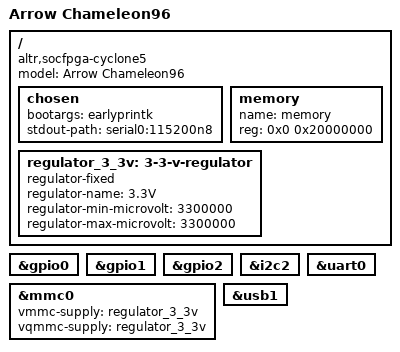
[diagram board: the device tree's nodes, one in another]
/*
 *  Copyright (C) 2017 Arrow Electronics, Inc.
 *
 * This program is free software; you can redistribute it and/or modify
 * it under the terms of the GNU General Public License as published by
 * the Free Software Foundation; either version 2 of the License, or
 * (at your option) any later version.
 *
 * This program is distributed in the hope that it will be useful,
 * but WITHOUT ANY WARRANTY; without even the implied warranty of
 * MERCHANTABILITY or FITNESS FOR A PARTICULAR PURPOSE.  See the
 * GNU General Public License for more details.
 *
 * You should have received a copy of the GNU General Public License
 * along with this program.  If not, see <http://www.gnu.org/licenses/>.
 */

#include "socfpga_cyclone5.dtsi"

/ {
	model = "Arrow Chameleon96";
	compatible = "altr,socfpga-cyclone5", "altr,socfpga";

	chosen {
		bootargs = "earlyprintk";
		stdout-path = "serial0:115200n8";
	};

	memory {
		name = "memory";
		device_type = "memory";
		reg = <0x0 0x20000000>; /* 512MB */
	};

	regulator_3_3v: 3-3-v-regulator {
		compatible = "regulator-fixed";
		regulator-name = "3.3V";
		regulator-min-microvolt = <3300000>;
		regulator-max-microvolt = <3300000>;
	};
};

&gpio0 {
	status = "okay";
};

&gpio1 {
	status = "okay";
};

&gpio2 {
	status = "okay";
};

&i2c2 {
	status = "okay";
};

&mmc0 {
	vmmc-supply = <&regulator_3_3v>;
	vqmmc-supply = <&regulator_3_3v>;
};

&uart0 {
	status = "okay";
};

&usb1 {
	status = "okay";
};
